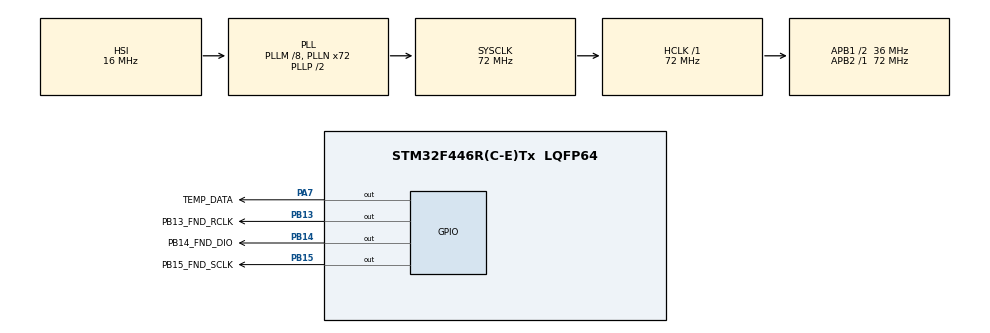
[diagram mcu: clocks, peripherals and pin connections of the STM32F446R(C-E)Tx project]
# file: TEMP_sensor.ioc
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Mcu.Family=STM32F4
Mcu.Name=STM32F446R(C-E)Tx
Mcu.Package=LQFP64
NVIC.PriorityGroup=NVIC_PRIORITYGROUP_4
NVIC.TIM2_IRQn=true\:0\:0\:false\:false\:true\:true\:true\:true
PA7.GPIO_Label=TEMP_DATA
PA7.GPIO_PuPd=GPIO_PULLUP
PA7.GPIO_Speed=GPIO_SPEED_FREQ_HIGH
PA7.PinState=GPIO_PIN_SET
PA7.Signal=GPIO_Output
PB13.GPIO_Label=PB13_FND_RCLK
PB13.GPIO_ModeDefaultOutputPP=GPIO_MODE_OUTPUT_PP
PB13.GPIO_PuPd=GPIO_PULLUP
PB13.GPIO_Speed=GPIO_SPEED_FREQ_HIGH
PB13.PinState=GPIO_PIN_SET
PB13.Signal=GPIO_Output
PB14.GPIO_Label=PB14_FND_DIO
PB14.GPIO_PuPd=GPIO_PULLUP
PB14.GPIO_Speed=GPIO_SPEED_FREQ_HIGH
PB14.PinState=GPIO_PIN_SET
PB14.Signal=GPIO_Output
PB15.GPIO_Label=PB15_FND_SCLK
PB15.GPIO_PuPd=GPIO_PULLUP
PB15.GPIO_Speed=GPIO_SPEED_FREQ_HIGH
PB15.PinState=GPIO_PIN_SET
PB15.Signal=GPIO_Output
ProjectManager.HeapSize=0x200
ProjectManager.StackSize=0x400
ProjectManager.TargetToolchain=STM32CubeIDE
RCC.AHBFreq_Value=72000000
RCC.APB1CLKDivider=RCC_HCLK_DIV2
RCC.APB1Freq_Value=36000000
RCC.APB1TimFreq_Value=72000000
RCC.APB2Freq_Value=72000000
RCC.APB2TimFreq_Value=72000000
RCC.CortexFreq_Value=72000000
RCC.HCLKFreq_Value=72000000
RCC.PLLM=8
RCC.PLLN=72
RCC.SYSCLKFreq_VALUE=72000000
RCC.SYSCLKSource=RCC_SYSCLKSOURCE_PLLCLK
RCC.USBFreq_Value=72000000
RCC.VCOOutputFreq_Value=144000000
TIM2.Period=4294967295
TIM2.Prescaler=(72-1)
VP_TIM2_VS_ClockSourceINT.Mode=Internal
board=custom

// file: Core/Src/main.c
/* USER CODE BEGIN Header */
/**
  ******************************************************************************
  * @file           : main.c
  * @brief          : Main program body
  ******************************************************************************
  * @attention
  *
  * Copyright (c) 2026 STMicroelectronics.
  * All rights reserved.
  *
  * This software is licensed under terms that can be found in the LICENSE file
  * in the root directory of this software component.
  * If no LICENSE file comes with this software, it is provided AS-IS.
  *
  ******************************************************************************
  */
/* USER CODE END Header */
#include "main.h"

/* USER CODE BEGIN Includes */

#include "FND_controller.h"
#include "ds18b20.h"

/* USER CODE END Includes */

TIM_HandleTypeDef htim2;

void SystemClock_Config(void);
static void MX_GPIO_Init(void);
static void MX_TIM2_Init(void);

int main(void)
{

  /* MCU Configuration--------------------------------------------------------*/

  /* Reset of all peripherals, Initializes the Flash interface and the Systick. */
  HAL_Init();

  /* Configure the system clock */
  SystemClock_Config();

  /* Initialize all configured peripherals */
  MX_GPIO_Init();
  MX_TIM2_Init();
  /* USER CODE BEGIN 2 */

  init_FND();

  Ds18b20_Init();

  /* USER CODE END 2 */

  /* Infinite loop */
  /* USER CODE BEGIN WHILE */
  while (1)
  {
	    Ds18b20_ManualConvert();

	    digit4_temper((int)(ds18b20[0].Temperature * 10), 0);

	    HAL_Delay(1000);

    /* USER CODE END WHILE */

  }
}

void SystemClock_Config(void)
{
  RCC_OscInitTypeDef RCC_OscInitStruct = {0};
  RCC_ClkInitTypeDef RCC_ClkInitStruct = {0};

  /** Configure the main internal regulator output voltage
  */
  __HAL_RCC_PWR_CLK_ENABLE();
  __HAL_PWR_VOLTAGESCALING_CONFIG(PWR_REGULATOR_VOLTAGE_SCALE3);

  /** Initializes the RCC Oscillators according to the specified parameters
  * in the RCC_OscInitTypeDef structure.
  */
  RCC_OscInitStruct.OscillatorType = RCC_OSCILLATORTYPE_HSI;
  RCC_OscInitStruct.HSIState = RCC_HSI_ON;
  RCC_OscInitStruct.HSICalibrationValue = RCC_HSICALIBRATION_DEFAULT;
  RCC_OscInitStruct.PLL.PLLState = RCC_PLL_ON;
  RCC_OscInitStruct.PLL.PLLSource = RCC_PLLSOURCE_HSI;
  RCC_OscInitStruct.PLL.PLLM = 8;
  RCC_OscInitStruct.PLL.PLLN = 72;
  RCC_OscInitStruct.PLL.PLLP = RCC_PLLP_DIV2;
  RCC_OscInitStruct.PLL.PLLQ = 2;
  RCC_OscInitStruct.PLL.PLLR = 2;
  if (HAL_RCC_OscConfig(&RCC_OscInitStruct) != HAL_OK)
  {
    Error_Handler();
  }

  /** Initializes the CPU, AHB and APB buses clocks
  */
  RCC_ClkInitStruct.ClockType = RCC_CLOCKTYPE_HCLK|RCC_CLOCKTYPE_SYSCLK
                              |RCC_CLOCKTYPE_PCLK1|RCC_CLOCKTYPE_PCLK2;
  RCC_ClkInitStruct.SYSCLKSource = RCC_SYSCLKSOURCE_PLLCLK;
  RCC_ClkInitStruct.AHBCLKDivider = RCC_SYSCLK_DIV1;
  RCC_ClkInitStruct.APB1CLKDivider = RCC_HCLK_DIV2;
  RCC_ClkInitStruct.APB2CLKDivider = RCC_HCLK_DIV1;

  if (HAL_RCC_ClockConfig(&RCC_ClkInitStruct, FLASH_LATENCY_2) != HAL_OK)
  {
    Error_Handler();
  }
}

static void MX_TIM2_Init(void)
{

  TIM_ClockConfigTypeDef sClockSourceConfig = {0};
  TIM_MasterConfigTypeDef sMasterConfig = {0};

  htim2.Instance = TIM2;
  htim2.Init.Prescaler = (72-1);
  htim2.Init.CounterMode = TIM_COUNTERMODE_UP;
  htim2.Init.Period = 4294967295;
  htim2.Init.ClockDivision = TIM_CLOCKDIVISION_DIV1;
  htim2.Init.AutoReloadPreload = TIM_AUTORELOAD_PRELOAD_DISABLE;
  if (HAL_TIM_Base_Init(&htim2) != HAL_OK)
  {
    Error_Handler();
  }
  sClockSourceConfig.ClockSource = TIM_CLOCKSOURCE_INTERNAL;
  if (HAL_TIM_ConfigClockSource(&htim2, &sClockSourceConfig) != HAL_OK)
  {
    Error_Handler();
  }
  sMasterConfig.MasterOutputTrigger = TIM_TRGO_RESET;
  sMasterConfig.MasterSlaveMode = TIM_MASTERSLAVEMODE_DISABLE;
  if (HAL_TIMEx_MasterConfigSynchronization(&htim2, &sMasterConfig) != HAL_OK)
  {
    Error_Handler();
  }

}

static void MX_GPIO_Init(void)
{
  GPIO_InitTypeDef GPIO_InitStruct = {0};

  /* GPIO Ports Clock Enable */
  __HAL_RCC_GPIOA_CLK_ENABLE();
  __HAL_RCC_GPIOB_CLK_ENABLE();

  /*Configure GPIO pin Output Level */
  HAL_GPIO_WritePin(TEMP_DATA_GPIO_Port, TEMP_DATA_Pin, GPIO_PIN_SET);

  /*Configure GPIO pin Output Level */
  HAL_GPIO_WritePin(GPIOB, PB13_FND_RCLK_Pin|PB14_FND_DIO_Pin|PB15_FND_SCLK_Pin, GPIO_PIN_SET);

  /*Configure GPIO pin : TEMP_DATA_Pin */
  GPIO_InitStruct.Pin = TEMP_DATA_Pin;
  GPIO_InitStruct.Mode = GPIO_MODE_OUTPUT_PP;
  GPIO_InitStruct.Pull = GPIO_PULLUP;
  GPIO_InitStruct.Speed = GPIO_SPEED_FREQ_HIGH;
  HAL_GPIO_Init(TEMP_DATA_GPIO_Port, &GPIO_InitStruct);

  /*Configure GPIO pins : PB13_FND_RCLK_Pin PB14_FND_DIO_Pin PB15_FND_SCLK_Pin */
  GPIO_InitStruct.Pin = PB13_FND_RCLK_Pin|PB14_FND_DIO_Pin|PB15_FND_SCLK_Pin;
  GPIO_InitStruct.Mode = GPIO_MODE_OUTPUT_PP;
  GPIO_InitStruct.Pull = GPIO_PULLUP;
  GPIO_InitStruct.Speed = GPIO_SPEED_FREQ_HIGH;
  HAL_GPIO_Init(GPIOB, &GPIO_InitStruct);

}

void Error_Handler(void)
{
  __disable_irq();
  while (1)
  {
  }
}
